# CONTROLSS_PWMXBAR_CONTROLSS_502D1000h register map
Vendor: Texas Instruments
Peripheral module from a debugger description file (folder AM263X).
Registers are 32-bit, read-write, reset 0x0 unless marked. A register's access mark holds for its fields unless they carry their own. Offsets are as the file gives them; lines under a group give offsets from that group; [hi:lo] are bit positions; {n}, {i} and the like mark numbered series; 'fields as' and 'values as' point back to an identical list; <NAME> marks a mode.

## CONTROLSS
0x10 CONTROLSS_PWMXBAR_STATUS ro — Output Signal Status.
  [29:0] PWMXBAR_STATUS_STS — Output Signal Status
0x14 CONTROLSS_PWMXBAR_FLAGINVERT — Output Signal Invert Before Latch.
  [29:0] PWMXBAR_FLAGINVERT_INVERT — Output Signal Invert Before Latch
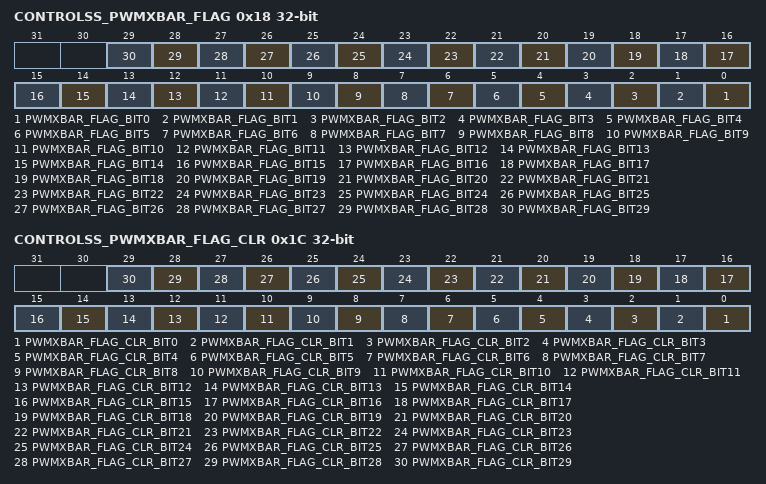
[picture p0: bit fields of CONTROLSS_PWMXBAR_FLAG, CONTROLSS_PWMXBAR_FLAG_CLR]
0x18 CONTROLSS_PWMXBAR_FLAG — Output Signal Latched Flag.
  [n] PWMXBAR_FLAG_BIT{n} (n=0..29) — Output Signal Latched Flag
0x1C CONTROLSS_PWMXBAR_FLAG_CLR — Output Signal Latched Flag Clear.
  [n] PWMXBAR_FLAG_CLR_BIT{n} (n=0..29) — Output Signal Latched Flag Clear
{0x100+0x40*i} CONTROLSS_PWMXBAR{i}_G0 (i=0..29) — PWM XBAR {i} Input Select.
  [19:0] PWMXBAR{i}_G0_SEL — PWM XBAR{i} G0 Input Select0:CMP12SS0.CTRIPL1:CMP12SS0.CTRIPH2:CMP12SS1.CTRIPL3:CMP12SS1.CTRIPH4:CMP12SS2.CTRIPL5:CMP12SS2.CTRIPH6:CMP12SS3.CTRIPL7:CMP12SS3.CTRIPH8:CMP12SS4.CTRIPL9:CMP12SS4.CTRIPH10:CMP12SS5.CTRIPL11:CMP12SS5.CTRIPH12:CMP12SS6.CTRIPL13:CMP12SS6.CTRIPH14:CMP12SS7.CTRIPL15:CMP12SS7.CTRIPH16:CMP12SS8.CTRIPL17:CMP12SS8.CTRIPH18:CMP12SS9.CTRIPL19:CMP12SS9.CTRIPH
{0x104+0x40*i} CONTROLSS_PWMXBAR{i}_G1 (i=0..29) — PWM XBAR {i} Input Select.
  [19:0] PWMXBAR{i}_G1_SEL — PWM XBAR{i} G1 Input Select0:CMP8SS0.CTRIPL1:CMP8SS0.CTRIPH2:CMP8SS1.CTRIPL3:CMP8SS1.CTRIPH4:CMP8SS2.CTRIPL5:CMP8SS2.CTRIPH6:CMP8SS3.CTRIPL7:CMP8SS3.CTRIPH8:CMP8SS4.CTRIPL9:CMP8SS4.CTRIPH10:CMP8SS5.CTRIPL11:CMP8SS5.CTRIPH12:CMP8SS6.CTRIPL13:CMP8SS6.CTRIPH14:CMP8SS7.CTRIPL15:CMP8SS7.CTRIPH16:CMP8SS8.CTRIPL17:CMP8SS8.CTRIPH18:CMP8SS9.CTRIPL19:CMP8SS9.CTRIPH
{0x108+0x40*i} CONTROLSS_PWMXBAR{i}_G2 (i=0..29) — PWM XBAR {i} Input Select.
  [23:0] PWMXBAR{i}_G2_SEL — PWM XBAR{i} G2 Input Select0:SDFM0.FILT1CEVT11:SDFM0.FILT1CEVT22:SDFM0.FILT1COMPHZ3:SDFM0.FILT2CEVT14:SDFM0.FILT2CEVT25:SDFM0.FILT2COMPHZ6:SDFM0.FILT3CEVT17:SDFM0.FILT3CEVT28:SDFM0.FILT3COMPHZ9:SDFM0.FILT4CEVT110:SDFM0.FILT4CEVT211:SDFM0.FILT4COMPHZ12:SDFM1.FILT1CEVT113:SDFM1.FILT1CEVT214:SDFM1.FILT1COMPHZ15:SDFM1.FILT2CEVT116:SDFM1.FILT2CEVT217:SDFM1.FILT2COMPHZ18:SDFM1.FILT3CEVT119:SDFM1.FILT3CEVT220:SDFM1.FILT3COMPHZ21:SDFM1.FILT4CEVT122:SDFM1.FILT4CEVT223:SDFM1.FILT4COMPHZ
{0x10C+0x40*i} CONTROLSS_PWMXBAR{i}_G3 (i=0..29) — PWM XBAR {i} Input Select.
  [19:0] PWMXBAR{i}_G3_SEL — PWM XBAR{i} G3 Input Select1:ADC0.EVT22:ADC0.EVT33:ADC0.EVT44:ADC1.EVT15:ADC1.EVT26:ADC1.EVT37:ADC1.EVT48:ADC2.EVT19:ADC2.EVT210:ADC2.EVT311:ADC2.EVT412:ADC3.EVT113:ADC3.EVT214:ADC3.EVT315:ADC3.EVT416:ADC4.EVT117:ADC4.EVT218:ADC4.EVT319:ADC4.EVT4
{0x110+0x40*i} CONTROLSS_PWMXBAR{i}_G4 (i=0..29) — PWM XBAR {i} Input Select.
  [31:0] PWMXBAR{i}_G4_SEL — PWM XBAR{i} G4 input bit select. Input source is INPUT XBAR.1:INPUT XBAR output bit[x] selected0:INPUT XBAR output bit[x] is de-selected
{0x114+0x40*i} CONTROLSS_PWMXBAR{i}_G5 (i=0..29) — PWM XBAR {i} Input Select.
  [31:0] PWMXBAR{i}_G5_SEL — PWM XBAR{i} G5 input bit select. Input source is PWM TRIPOUT.1:PWM TRIPOUT bit[x] selected0:PWM TRIPOUT bit[x] is de-selected
{0x118+0x40*i} CONTROLSS_PWMXBAR{i}_G6 (i=0..29) — PWM XBAR {i} Input Select.
  [31:0] PWMXBAR{i}_G6_SEL — PWM XBAR{i} G6 input bit select. Input source is PWM DEL TRIP1:PWM DEL TRIP bit[x] selected0:PWM DEL TRIP bit[x] is de-selected
{0x11C+0x40*i} CONTROLSS_PWMXBAR{i}_G7 (i=0..29) — PWM XBAR {i} Input Select.
  [31:0] PWMXBAR{i}_G7_SEL — PWM XBAR{i} G7 input bit select. Input source is PWM DEL ACTIVE1:PWM DEL ACTIVE bit[x] selected0:PWM DEL ACTIVE bit[x] is de-selected
0x120 CONTROLSS_PWMXBAR0_G8 — PWM XBAR 0 Input Select.
  [28:0] PWMXBAR0_G8_SEL — PWM XBAR0 G8 Input Select0:EQEP0.ERR1:EQEP1.ERR2:EQEP2.ERR63:FSIRX0.RX_TRIG4107:FSIRX1.RX_TRIG41411:FSIRX2.RX_TRIG41815:FSIRX3.RX_TRIG42819:ECAP[9:0].TRIPOUT
{0x120+0x40*i} CONTROLSS_PWMXBAR{i}_G8 (i=1..29) — PWM XBAR {i} Input Select.
  [28:0] PWMXBAR{i}_G8_SEL — PWM XBAR{i} G8 Input Select0:EQEP0.ERR1:EQEP1.ERR2:EQEP2.ERR63:FSIRX0.RX_TRIG4107:FSIRX1.RX_TRIG41411:FSIRX2.RX_TRIG41815:FSIRX3.RX_TRIG4 2819:ECAP[9:0].TRIPOUT
